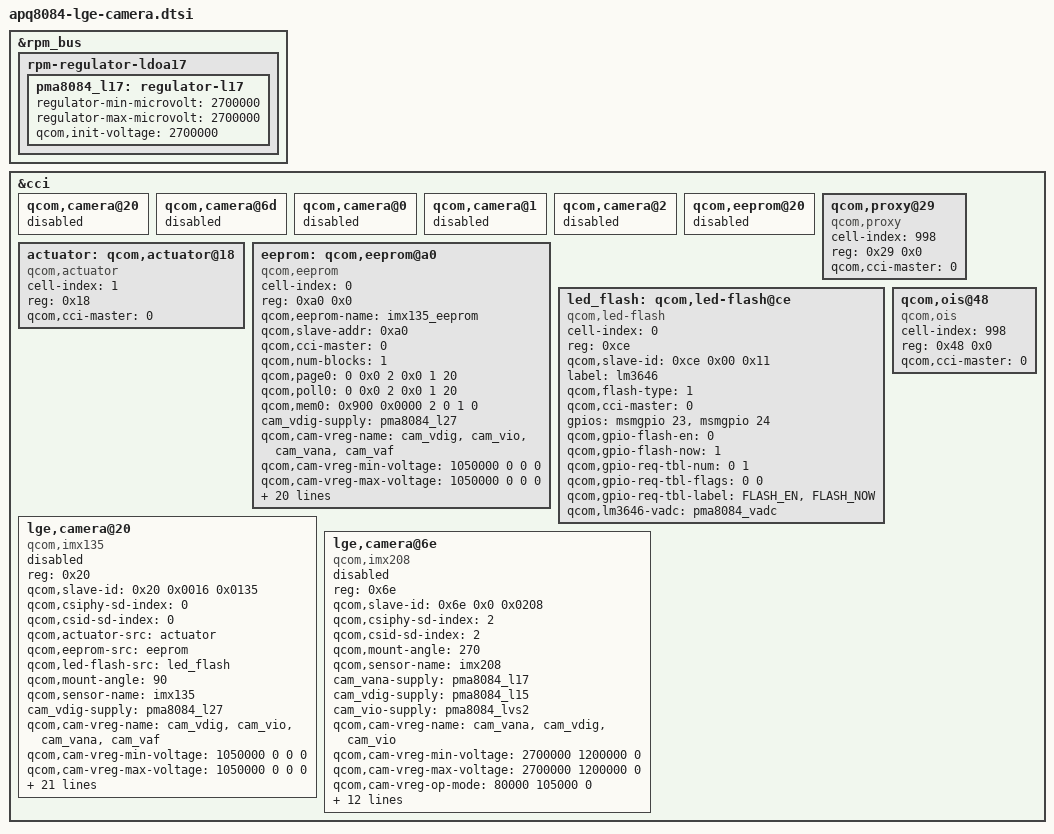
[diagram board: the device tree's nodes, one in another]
/* Copyright (c) 2012, Code Aurora Forum. All rights reserved.
 *
 * This program is free software; you can redistribute it and/or modify
 * it under the terms of the GNU General Public License version 2 and
 * only version 2 as published by the Free Software Foundation.
 *
 * This program is distributed in the hope that it will be useful,
 * but WITHOUT ANY WARRANTY; without even the implied warranty of
 * MERCHANTABILITY or FITNESS FOR A PARTICULAR PURPOSE.  See the
 * GNU General Public License for more details.
 */

&rpm_bus {
	rpm-regulator-ldoa17 {
		status = "okay";
		pma8084_l17: regulator-l17 {
			regulator-min-microvolt = <2700000>;
			regulator-max-microvolt = <2700000>;
			qcom,init-voltage = <2700000>;
			status = "okay";
		};
	};
};

&cci {
	qcom,camera@20 {
		status = "disable";
	};

	qcom,camera@6d {
		status = "disable";
	};

	qcom,camera@0 {
		status = "disable";
	};

	qcom,camera@1 {
		status = "disable";
	};

	qcom,camera@2 {
		status = "disable";
	};

	qcom,eeprom@20 {
		status = "disable";
	};

	qcom,proxy@29 {
		cell-index = <998>;
		reg = <0x29 0x0>;
		compatible = "qcom,proxy";
		qcom,cci-master = <0>;
	};

	actuator: qcom,actuator@18 {
		cell-index = <1>;
		reg = <0x18>;
		compatible = "qcom,actuator";
		qcom,cci-master = <0>;
	};

	eeprom: qcom,eeprom@a0 {
		cell-index = <0>;
		reg = <0xa0 0x0>;
		qcom,eeprom-name = "imx135_eeprom";
		compatible = "qcom,eeprom";
		qcom,slave-addr = <0xa0>;
		qcom,cci-master = <0>;
		qcom,num-blocks = <1>;
		qcom,page0 = <0 0x0 2 0x0 1 20>;
		qcom,poll0 = <0 0x0 2 0x0 1 20>;
		qcom,mem0 = <0x900 0x0000 2 0 1 0>;
		cam_vdig-supply = <&pma8084_l27>;
		qcom,cam-vreg-name = "cam_vdig", "cam_vio", "cam_vana",
			"cam_vaf";
		qcom,cam-vreg-min-voltage = <1050000 0 0 0>;
		qcom,cam-vreg-max-voltage = <1050000 0 0 0>;
		qcom,cam-vreg-op-mode = <105000 0 0 0>;
		qcom,gpio-no-mux = <0>;
		gpios = <&msmgpio 15 0>,	//MCLK
			<&msmgpio 39 0>,	// 13M_VANA_EN
			<&msmgpio 57 0>,	// 13M_VIO_EN
			<&msmgpio 36 0>,	// MAIN_CAM_RESET
			<&msmgpio 38 0>,	// 13M_VCM_EN : OIS_MVDD
			<&msmgpio 37 0>,	// OIS_LDO_EN : OIS_VDD
			<&msmgpio 120 0>;	// OIS_RESET
		qcom,gpio-vana = <1>;
		qcom,gpio-vio = <2>;
		qcom,gpio-reset = <3>;
		qcom,gpio-vaf = <4>;
		qcom,gpio-ois-ldo = <5>;
		qcom,gpio-ois-reset = <6>;
		qcom,gpio-req-tbl-num = <0 1 2 3 4 5 6>;
		qcom,gpio-req-tbl-flags = <0 0 0 0 0 0 0>;
		qcom,gpio-req-tbl-label =  "CAMIF_MCLK",
			"MAIN_VANA_EN",
			"MAIN_VIO_EN",
			"CAM_RESET1",
			"MAIN_VCM_EN",
			"OIS_LDO_EN",
			"OIS_RESET";
		qcom,cam-power-seq-type = "sensor_gpio";
		qcom,cam-power-seq-val = "sensor_gpio_vio";
		qcom,cam-power-seq-cfg-val = <1>;
		qcom,cam-power-seq-delay = <10>;
	};

	led_flash: qcom,led-flash@ce {
		cell-index = <0>;
		reg = <0xce>;
		qcom,slave-id = <0xce 0x00 0x11>;
		compatible = "qcom,led-flash";
		label = "lm3646";
		qcom,flash-type = <1>;
		qcom,cci-master = <0>;
		gpios = <&msmgpio 23 0>,
			<&msmgpio 24 0>;
		qcom,gpio-flash-en = <0>;
		qcom,gpio-flash-now = <1>;
		qcom,gpio-req-tbl-num = <0 1>;
		qcom,gpio-req-tbl-flags = <0 0>;
		qcom,gpio-req-tbl-label = "FLASH_EN",
			"FLASH_NOW";
		qcom,lm3646-vadc = <&pma8084_vadc>;
	};

	qcom,ois@48 {
		cell-index = <998>;
		reg = <0x48 0x0>;
		compatible = "qcom,ois";
		qcom,cci-master = <0>;
	};

	lge,camera@20 {
		compatible = "qcom,imx135";
		reg = <0x20>;
		qcom,slave-id = <0x20 0x0016 0x0135>;
		qcom,csiphy-sd-index = <0>;
		qcom,csid-sd-index = <0>;
		qcom,actuator-src = <&actuator>;
		qcom,eeprom-src = <&eeprom>;
		qcom,led-flash-src = <&led_flash>;
		qcom,mount-angle = <90>;
		qcom,sensor-name = "imx135";
		cam_vdig-supply = <&pma8084_l27>;
		qcom,cam-vreg-name = "cam_vdig", "cam_vio", "cam_vana",
			"cam_vaf";
		qcom,cam-vreg-min-voltage = <1050000 0 0 0>;
		qcom,cam-vreg-max-voltage = <1050000 0 0 0>;
		qcom,cam-vreg-op-mode = <105000 0 0 0>;
		qcom,gpio-no-mux = <0>;
		gpios = <&msmgpio 15 0>,	//MCLK
			<&msmgpio 39 0>,	// 13M_VANA_EN
			<&msmgpio 57 0>,	// 13M_VIO_EN
			<&msmgpio 36 0>,	// MAIN_CAM_RESET
			<&msmgpio 38 0>,	// 13M_VCM_EN : OIS_MVDD
			<&msmgpio 37 0>,	// OIS_LDO_EN : OIS_VDD
			<&msmgpio 120 0>;	// OIS_RESET
		qcom,gpio-vana = <1>;
		qcom,gpio-vio = <2>;
		qcom,gpio-reset = <3>;
		qcom,gpio-vaf = <4>;
		qcom,gpio-ois-ldo = <5>;
		qcom,gpio-ois-reset = <6>;
		qcom,gpio-req-tbl-num = <0 1 2 3 4 5 6>;
		qcom,gpio-req-tbl-flags = <0 0 0 0 0 0 0>;
		qcom,gpio-req-tbl-label =  "CAMIF_MCLK",
			"MAIN_VANA_EN",
			"MAIN_VIO_EN",
			"CAM_RESET1",
			"MAIN_VCM_EN",
			"OIS_LDO_EN",
			"OIS_RESET";
		qcom,csi-lane-assign = <0x4320>;
		qcom,csi-lane-mask = <0x1F>;
		qcom,sensor-position = <0>;
		qcom,sensor-mode = <0>;
		qcom,cci-master = <0>;
		status = "disable";
	};

	lge,camera@6e {
		compatible = "qcom,imx208";
		reg = <0x6e>;
		qcom,slave-id = <0x6e 0x0 0x0208>;
		qcom,csiphy-sd-index = <2>;
		qcom,csid-sd-index = <2>;
		qcom,mount-angle = <270>;
		qcom,sensor-name = "imx208";
		cam_vana-supply = <&pma8084_l17>;
		cam_vdig-supply = <&pma8084_l15>;
		cam_vio-supply = <&pma8084_lvs2>;
		qcom,cam-vreg-name =  "cam_vana", "cam_vdig", "cam_vio";
		qcom,cam-vreg-min-voltage = <2700000 1200000 0>;
		qcom,cam-vreg-max-voltage = <2700000 1200000 0>;
		qcom,cam-vreg-op-mode = <80000 105000 0>;
		qcom,gpio-no-mux = <0>;
		gpios = <&msmgpio 17 0>,
			<&msmgpio 25 0>;
		qcom,gpio-reset = <1>;
		qcom,gpio-req-tbl-num = <0 1>;
		qcom,gpio-req-tbl-flags = <0 0>;
		qcom,gpio-req-tbl-label = "CAMIF_MCLK2",
			"CAM_RESET2";
		qcom,csi-lane-assign = <0x4320>;
		qcom,csi-lane-mask = <0x3>;
		qcom,sensor-position = <1>;
		qcom,sensor-mode = <1>;
		qcom,cci-master = <1>;
		status = "disable";
	};
};
